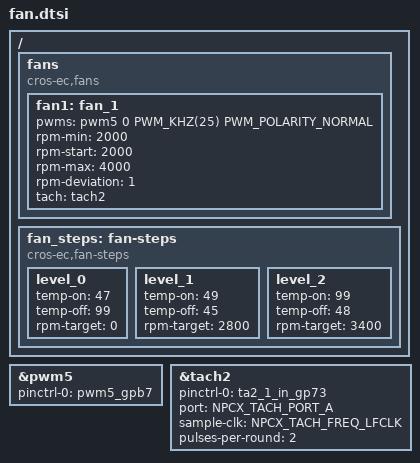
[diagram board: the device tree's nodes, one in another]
/* Copyright 2026 The ChromiumOS Authors
 * Use of this source code is governed by a BSD-style license that can be
 * found in the LICENSE file.
 */

/ {
	fans {
		compatible = "cros-ec,fans";

		fan1: fan_1 {
			pwms = <&pwm5 0 PWM_KHZ(25) PWM_POLARITY_NORMAL>;
			rpm-min = <2000>;
			rpm-start = <2000>;
			rpm-max = <4000>;
			rpm-deviation = <1>;
			tach = <&tach2>;
		};
	};

	fan_steps: fan-steps {
		compatible = "cros-ec,fan-steps";
		level_0 {
			temp-on = <47>;
			temp-off = <99>;
			rpm-target = <0>;
		};
		level_1 {
			temp-on = <49>;
			temp-off = <45>;
			rpm-target = <2800>;
		};
		level_2 {
			temp-on = <99>;
			temp-off = <48>;
			rpm-target = <3400>;
		};
	};
};

&pwm5 {
	status = "okay";
	pinctrl-0 = <&pwm5_gpb7>;
	pinctrl-names = "default";
};

&tach2 {
	status = "okay";
	pinctrl-0 = <&ta2_1_in_gp73>;
	pinctrl-names = "default";
	port = <NPCX_TACH_PORT_A>;
	sample-clk = <NPCX_TACH_FREQ_LFCLK>;
	pulses-per-round = <2>;
};

